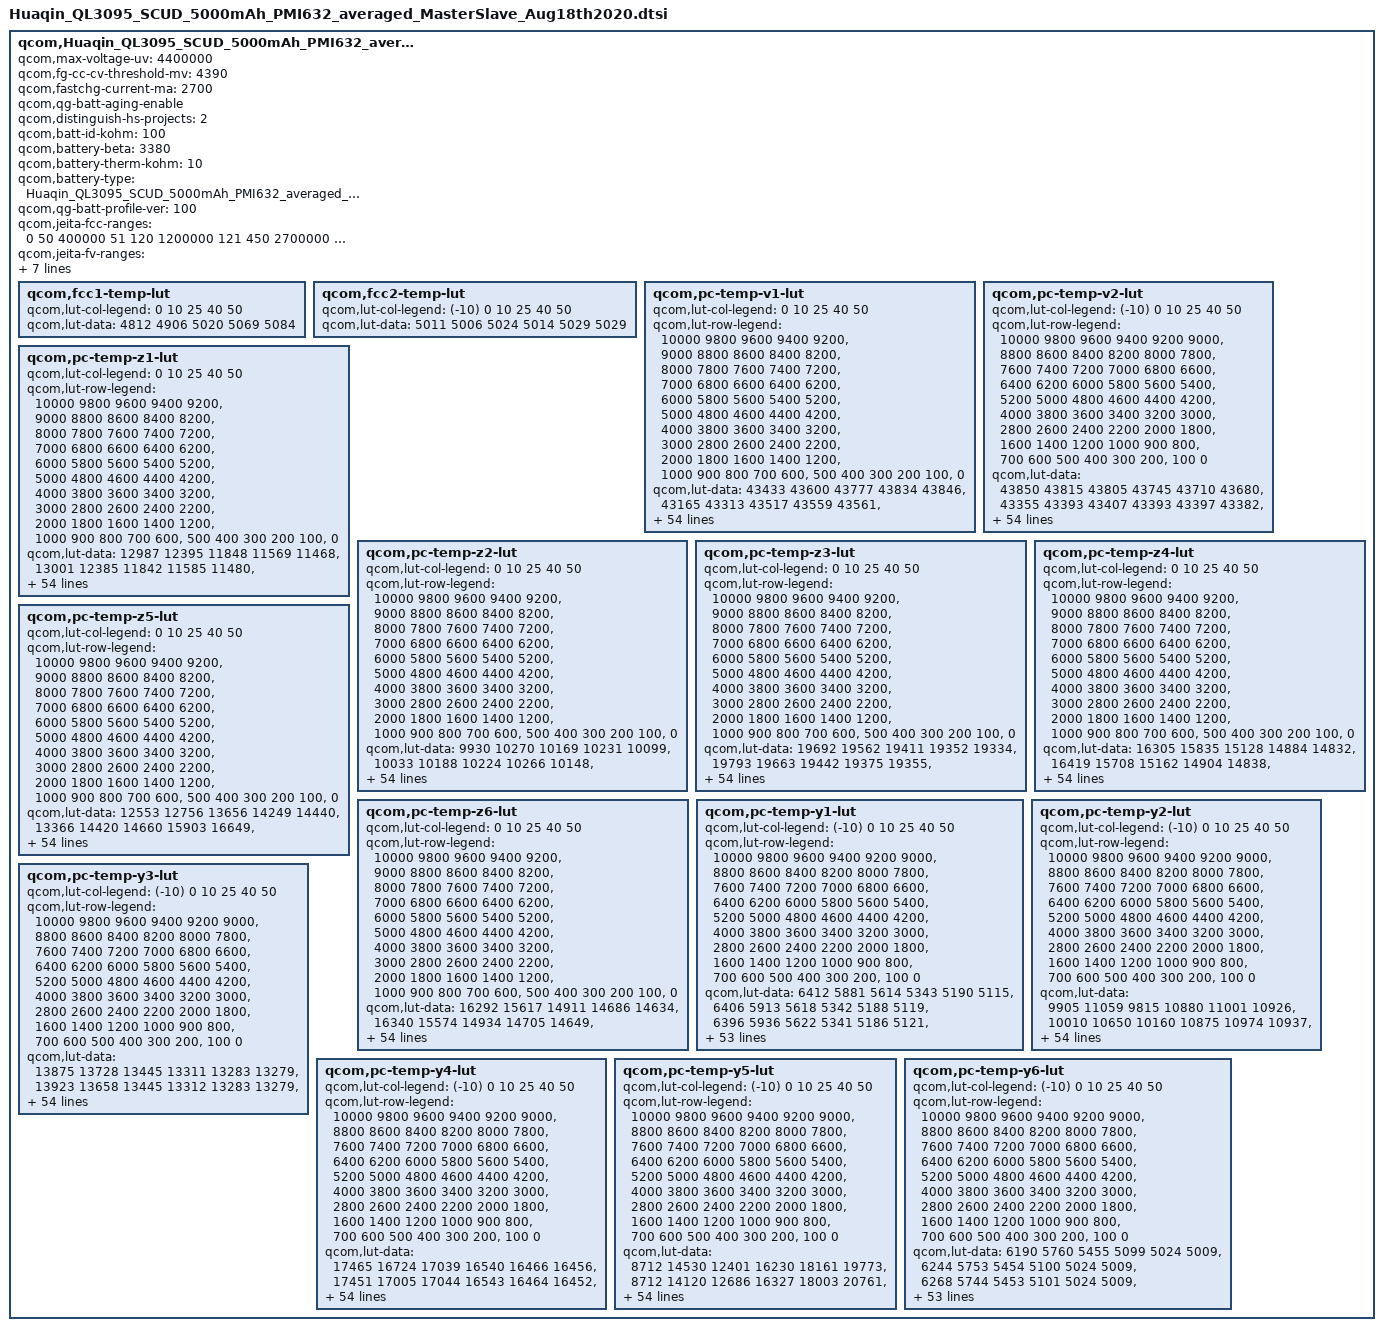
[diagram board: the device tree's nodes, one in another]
qcom,Huaqin_QL3095_SCUD_5000mAh_PMI632_averaged_MasterSlave_Aug18th2020 {
    /* Huaqin_QL3095_SCUD_5000mAh_PMI632_averaged_MasterSlave_Aug18th2020 */
	qcom,max-voltage-uv = <4400000>;
	qcom,fg-cc-cv-threshold-mv = <4390>;
	qcom,fastchg-current-ma = <2700>;
	/* HS60 add for SR-ZQL1695-01-357 Import battery aging by gaochao at 2019/08/29 start */
	qcom,qg-batt-aging-enable;
	/* HS60 add for SR-ZQL1695-01-357 Import battery aging by gaochao at 2019/08/29 end */
	/* HS50 add for SR-QL3095-01-67 Distinguish HS60, HS70 and HS50 charging by wenyaqi at 2020/8/3 start */
	qcom,distinguish-hs-projects = <2>;
	/* HS50 add for SR-QL3095-01-67 Distinguish HS60, HS70 and HS50 charging by wenyaqi at 2020/8/3 end */
	qcom,batt-id-kohm = <100>;
	/* HS50 add for HS50-186 fix hw jeita by wenyaqi at 2020/8/22 start */
	qcom,battery-beta = <3380>;
	/* HS50 add for HS50-186 fix hw jeita by wenyaqi at 2020/8/22 end */
	qcom,battery-therm-kohm = <10>;

	/* HS50 add for SR-QL3095-01-91 Import SCDU 5000mAh battery profile by zhangjin at 2020/8/19 start */
	qcom,battery-type = "Huaqin_QL3095_SCUD_5000mAh_PMI632_averaged_MasterSlave_Aug18th2020";
	/* HS50 add for SR-QL3095-01-91 Import SCDU 5000mAh battery profile by zhangjin at 2020/8/19 end */
	qcom,qg-batt-profile-ver = <100>;

	qcom,jeita-fcc-ranges = <0   50   400000
				 51   120   1200000
				 121 450  2700000
				 451 500  2200000>;
	qcom,jeita-fv-ranges =  <0   50  4400000
				 51   120  4400000
				 121 450  4400000
				 451 500  4200000>;

	/* HS60 add for SR-ZQL1695-01-357 Import battery aging by gaochao at 2019/08/29 start */
	qcom,vfloat-ranges = <0 299 4400000
	                      300 399 4380000
                              400 699 4360000
                              700 999 4340000
                              1000 9999 4290000>;

	qcom,vbat-rechg-ranges = <0 299 4330000
                                  300 399 4310000
                                  400 699 4290000
                                  700 999 4270000
                                  1000 9999 4220000>;
	/* HS60 add for SR-ZQL1695-01-357 Import battery aging by gaochao at 2019/08/29 end */

	/* COOL = 15 DegC, WARM = 45 DegC */
	/* HS50 add for HS50-186 fix hw jeita by wenyaqi at 2020/8/22 start */
	qcom,jeita-soft-thresholds = <0x2554 0xFDC>;
	/* COLD = 0 DegC, HOT = 50 DegC */
	qcom,jeita-hard-thresholds = <0x36B9 0xDBF>;
	/* HS50 add for HS50-186 fix hw jeita by wenyaqi at 2020/8/22 end */

	qcom,fcc1-temp-lut {
		qcom,lut-col-legend = <0 10 25 40 50>;
		qcom,lut-data = <4812 4906 5020 5069 5084>;
	};

	qcom,fcc2-temp-lut {
		qcom,lut-col-legend = <(-10) 0 10 25 40 50>;
		qcom,lut-data = <5011 5006 5024 5014 5029 5029>;
	};

	qcom,pc-temp-v1-lut {
		qcom,lut-col-legend = <0 10 25 40 50>;
		qcom,lut-row-legend = <10000 9800 9600 9400 9200>,
			<9000 8800 8600 8400 8200>,
			<8000 7800 7600 7400 7200>,
			<7000 6800 6600 6400 6200>,
			<6000 5800 5600 5400 5200>,
			<5000 4800 4600 4400 4200>,
			<4000 3800 3600 3400 3200>,
			<3000 2800 2600 2400 2200>,
			<2000 1800 1600 1400 1200>,
			<1000 900 800 700 600>,
			<500 400 300 200 100>,
			<0>;
		qcom,lut-data = <43433 43600 43777 43834 43846>,
			<43165 43313 43517 43559 43561>,
			<42925 43054 43243 43296 43301>,
			<42697 42821 42985 43042 43053>,
			<42477 42599 42746 42802 42814>,
			<42265 42378 42516 42571 42585>,
			<42060 42162 42290 42342 42357>,
			<41858 41952 42071 42115 42131>,
			<41664 41747 41855 41891 41906>,
			<41486 41549 41639 41671 41683>,
			<41331 41376 41432 41456 41462>,
			<41155 41217 41253 41249 41245>,
			<40908 41026 41087 41054 41033>,
			<40612 40756 40881 40852 40826>,
			<40339 40465 40596 40614 40617>,
			<40076 40217 40318 40369 40413>,
			<39859 39987 40110 40176 40228>,
			<39726 39818 39935 40018 40064>,
			<39632 39719 39793 39871 39906>,
			<39536 39636 39688 39735 39754>,
			<39428 39521 39577 39596 39600>,
			<39317 39376 39401 39412 39415>,
			<39199 39211 39182 39176 39184>,
			<39072 38995 38986 38968 38977>,
			<38941 38768 38804 38810 38819>,
			<38797 38629 38655 38676 38686>,
			<38652 38539 38557 38568 38573>,
			<38545 38469 38480 38479 38476>,
			<38462 38408 38407 38394 38386>,
			<38398 38358 38337 38311 38301>,
			<38351 38313 38274 38234 38223>,
			<38314 38272 38217 38165 38152>,
			<38282 38237 38165 38103 38087>,
			<38252 38207 38118 38048 38026>,
			<38227 38182 38078 38000 37973>,
			<38205 38156 38040 37955 37922>,
			<38187 38133 38006 37909 37867>,
			<38163 38104 37972 37863 37810>,
			<38117 38054 37922 37803 37741>,
			<38046 37974 37846 37722 37654>,
			<37960 37881 37753 37627 37554>,
			<37841 37773 37648 37521 37447>,
			<37703 37645 37522 37397 37324>,
			<37539 37481 37364 37246 37170>,
			<37386 37322 37211 37099 37029>,
			<37283 37213 37111 37004 36937>,
			<37255 37186 37080 36976 36909>,
			<37245 37160 37060 36957 36894>,
			<37211 37137 37045 36945 36878>,
			<37176 37109 37013 36911 36838>,
			<37046 36962 36849 36718 36626>,
			<36633 36548 36435 36304 36206>,
			<36082 35988 35872 35740 35642>,
			<35330 35226 35105 34971 34871>,
			<34143 34039 33916 33780 33675>,
			<30000 30000 30000 30000 30000>;
	};

	qcom,pc-temp-v2-lut {
		qcom,lut-col-legend = <(-10) 0 10 25 40 50>;
		qcom,lut-row-legend = <10000 9800 9600 9400 9200 9000>,
			<8800 8600 8400 8200 8000 7800>,
			<7600 7400 7200 7000 6800 6600>,
			<6400 6200 6000 5800 5600 5400>,
			<5200 5000 4800 4600 4400 4200>,
			<4000 3800 3600 3400 3200 3000>,
			<2800 2600 2400 2200 2000 1800>,
			<1600 1400 1200 1000 900 800>,
			<700 600 500 400 300 200>,
			<100 0>;
		qcom,lut-data = <43850 43815 43805 43745 43710 43680>,
			<43355 43393 43407 43393 43397 43382>,
			<42952 43021 43054 43077 43107 43104>,
			<42672 42706 42754 42803 42844 42846>,
			<42481 42433 42498 42565 42606 42608>,
			<42271 42201 42259 42337 42376 42376>,
			<41896 42018 42034 42109 42147 42146>,
			<41536 41851 41816 41886 41922 41919>,
			<41487 41636 41573 41665 41700 41697>,
			<41539 41351 41295 41445 41481 41478>,
			<41571 41176 41095 41237 41265 41263>,
			<41445 41143 41009 41054 41051 41050>,
			<41164 41120 40935 40875 40840 40841>,
			<40765 40953 40722 40658 40636 40639>,
			<40091 40308 40236 40394 40437 40441>,
			<39630 39809 39880 40148 40243 40251>,
			<39500 39669 39749 39941 40050 40069>,
			<39408 39571 39649 39759 39866 39895>,
			<39231 39426 39518 39622 39710 39734>,
			<38928 39234 39366 39522 39577 39585>,
			<38678 39049 39197 39400 39424 39420>,
			<38508 38898 38994 39192 39213 39209>,
			<38369 38751 38787 38952 38988 38991>,
			<38294 38563 38628 38764 38802 38806>,
			<38245 38320 38498 38605 38635 38639>,
			<38199 38161 38362 38471 38496 38499>,
			<38152 38108 38183 38361 38386 38388>,
			<38105 38072 38027 38265 38290 38291>,
			<38057 38033 37968 38177 38202 38201>,
			<38009 37995 37938 38095 38122 38117>,
			<37960 37958 37909 38020 38049 38043>,
			<37912 37919 37879 37947 37982 37976>,
			<37864 37880 37847 37882 37920 37914>,
			<37813 37841 37815 37830 37857 37851>,
			<37761 37804 37782 37788 37797 37790>,
			<37708 37763 37743 37744 37728 37714>,
			<37653 37718 37697 37695 37641 37607>,
			<37595 37668 37643 37640 37550 37494>,
			<37532 37610 37577 37573 37469 37405>,
			<37465 37543 37499 37493 37393 37327>,
			<37396 37468 37413 37406 37312 37245>,
			<37325 37377 37314 37310 37227 37158>,
			<37252 37273 37216 37200 37122 37054>,
			<37181 37160 37126 37063 36980 36917>,
			<37108 37053 37024 36944 36855 36795>,
			<37019 36958 36921 36871 36807 36753>,
			<36971 36917 36865 36853 36797 36744>,
			<36922 36881 36818 36834 36784 36729>,
			<36855 36828 36769 36808 36760 36706>,
			<36759 36747 36690 36755 36697 36633>,
			<36578 36580 36538 36593 36456 36361>,
			<36248 36197 36216 36158 35979 35871>,
			<35706 35598 35663 35545 35344 35228>,
			<34886 34726 34869 34705 34468 34334>,
			<33559 33344 33625 33352 33190 33052>,
			<29210 29419 28513 28298 28499 28549>;
	};

	qcom,pc-temp-z1-lut {
		qcom,lut-col-legend = <0 10 25 40 50>;
		qcom,lut-row-legend = <10000 9800 9600 9400 9200>,
			<9000 8800 8600 8400 8200>,
			<8000 7800 7600 7400 7200>,
			<7000 6800 6600 6400 6200>,
			<6000 5800 5600 5400 5200>,
			<5000 4800 4600 4400 4200>,
			<4000 3800 3600 3400 3200>,
			<3000 2800 2600 2400 2200>,
			<2000 1800 1600 1400 1200>,
			<1000 900 800 700 600>,
			<500 400 300 200 100>,
			<0>;
		qcom,lut-data = <12987 12395 11848 11569 11468>,
			<13001 12385 11842 11585 11480>,
			<12990 12381 11847 11582 11480>,
			<12978 12380 11847 11577 11479>,
			<12985 12381 11838 11573 11477>,
			<13001 12374 11827 11568 11474>,
			<13007 12357 11820 11564 11472>,
			<12985 12347 11814 11559 11471>,
			<12951 12343 11811 11557 11470>,
			<12937 12341 11810 11557 11470>,
			<12937 12334 11810 11558 11470>,
			<12935 12319 11809 11558 11470>,
			<12913 12300 11807 11558 11473>,
			<12868 12266 11802 11558 11475>,
			<12833 12235 11783 11549 11471>,
			<12798 12232 11768 11535 11463>,
			<12772 12236 11767 11533 11461>,
			<12763 12238 11768 11535 11462>,
			<12757 12240 11769 11538 11463>,
			<12754 12243 11776 11541 11465>,
			<12760 12247 11783 11544 11466>,
			<12768 12255 11785 11544 11466>,
			<12772 12260 11786 11543 11465>,
			<12776 12261 11787 11543 11465>,
			<12780 12262 11790 11544 11465>,
			<12783 12265 11792 11545 11466>,
			<12786 12276 11794 11547 11467>,
			<12791 12284 11796 11549 11469>,
			<12798 12284 11800 11552 11471>,
			<12804 12281 11805 11555 11473>,
			<12807 12281 11811 11558 11476>,
			<12808 12286 11814 11561 11479>,
			<12810 12290 11817 11564 11482>,
			<12823 12292 11820 11568 11486>,
			<12840 12294 11823 11572 11489>,
			<12844 12298 11827 11576 11492>,
			<12842 12314 11831 11580 11495>,
			<12842 12332 11837 11584 11498>,
			<12856 12339 11840 11587 11501>,
			<12878 12343 11844 11590 11503>,
			<12889 12344 11847 11592 11504>,
			<12894 12350 11850 11595 11507>,
			<12895 12354 11853 11598 11509>,
			<12899 12355 11859 11602 11511>,
			<12908 12370 11868 11606 11514>,
			<12938 12370 11876 11609 11515>,
			<12919 12384 11879 11609 11514>,
			<12909 12364 11877 11609 11516>,
			<12922 12368 11884 11610 11517>,
			<12911 12375 11875 11614 11520>,
			<12952 12379 11892 11620 11525>,
			<12957 12395 11893 11629 11532>,
			<12962 12420 11904 11640 11542>,
			<12974 12437 11923 11653 11555>,
			<12974 12437 11923 11653 11555>,
			<12974 12437 11923 11653 11555>;
	};

	qcom,pc-temp-z2-lut {
		qcom,lut-col-legend = <0 10 25 40 50>;
		qcom,lut-row-legend = <10000 9800 9600 9400 9200>,
			<9000 8800 8600 8400 8200>,
			<8000 7800 7600 7400 7200>,
			<7000 6800 6600 6400 6200>,
			<6000 5800 5600 5400 5200>,
			<5000 4800 4600 4400 4200>,
			<4000 3800 3600 3400 3200>,
			<3000 2800 2600 2400 2200>,
			<2000 1800 1600 1400 1200>,
			<1000 900 800 700 600>,
			<500 400 300 200 100>,
			<0>;
		qcom,lut-data = <9930 10270 10169 10231 10099>,
			<10033 10188 10224 10266 10148>,
			<10075 10163 10287 10378 10263>,
			<10100 10166 10315 10460 10401>,
			<10113 10168 10313 10449 10391>,
			<10123 10169 10311 10413 10306>,
			<10127 10170 10419 10390 10256>,
			<10128 10170 10651 10379 10210>,
			<10129 10169 10706 10369 10168>,
			<10129 10168 10489 10349 10162>,
			<10129 10172 10297 10325 10156>,
			<10128 10182 10400 10320 10156>,
			<10111 10193 10643 10324 10166>,
			<10079 10204 10710 10331 10182>,
			<10066 10213 10548 10383 10205>,
			<10066 10219 10395 10460 10234>,
			<10067 10223 10363 10447 10245>,
			<10075 10230 10335 10299 10245>,
			<10095 10254 10330 10207 10247>,
			<10115 10291 10357 10226 10267>,
			<10132 10326 10399 10271 10302>,
			<10150 10365 10465 10365 10339>,
			<10168 10398 10547 10562 10385>,
			<10186 10429 10563 10657 10410>,
			<10206 10453 10514 10516 10408>,
			<10229 10458 10473 10342 10402>,
			<10253 10455 10483 10325 10406>,
			<10271 10452 10507 10337 10424>,
			<10287 10449 10517 10355 10430>,
			<10299 10448 10522 10432 10386>,
			<10307 10448 10526 10507 10326>,
			<10313 10458 10528 10510 10295>,
			<10321 10470 10531 10498 10274>,
			<10335 10479 10536 10483 10268>,
			<10351 10486 10547 10459 10278>,
			<10364 10495 10560 10438 10296>,
			<10374 10506 10568 10433 10325>,
			<10386 10518 10576 10439 10369>,
			<10405 10535 10588 10459 10409>,
			<10428 10556 10610 10545 10449>,
			<10446 10564 10625 10616 10474>,
			<10460 10557 10628 10609 10466>,
			<10478 10552 10628 10582 10449>,
			<10515 10573 10627 10522 10441>,
			<10802 10739 10673 10512 10447>,
			<10859 10804 10687 10520 10450>,
			<10762 10809 10672 10504 10448>,
			<10475 10801 10664 10497 10448>,
			<10678 10791 10654 10514 10456>,
			<10645 10815 10656 10591 10543>,
			<10406 10852 10697 10535 10486>,
			<10703 10813 10644 10425 10262>,
			<10202 10729 10573 10368 10224>,
			<9771 10646 10483 10314 10170>,
			<9771 10646 10483 10314 10170>,
			<9771 10646 10483 10314 10170>;
	};

	qcom,pc-temp-z3-lut {
		qcom,lut-col-legend = <0 10 25 40 50>;
		qcom,lut-row-legend = <10000 9800 9600 9400 9200>,
			<9000 8800 8600 8400 8200>,
			<8000 7800 7600 7400 7200>,
			<7000 6800 6600 6400 6200>,
			<6000 5800 5600 5400 5200>,
			<5000 4800 4600 4400 4200>,
			<4000 3800 3600 3400 3200>,
			<3000 2800 2600 2400 2200>,
			<2000 1800 1600 1400 1200>,
			<1000 900 800 700 600>,
			<500 400 300 200 100>,
			<0>;
		qcom,lut-data = <19692 19562 19411 19352 19334>,
			<19793 19663 19442 19375 19355>,
			<19819 19688 19474 19398 19373>,
			<19830 19680 19485 19412 19384>,
			<19827 19669 19485 19412 19385>,
			<19815 19662 19485 19411 19385>,
			<19800 19655 19490 19411 19384>,
			<19783 19647 19499 19410 19383>,
			<19764 19638 19500 19410 19382>,
			<19749 19629 19485 19407 19380>,
			<19735 19618 19470 19403 19377>,
			<19727 19606 19469 19401 19376>,
			<19732 19596 19472 19400 19376>,
			<19742 19590 19472 19399 19375>,
			<19746 19584 19467 19398 19374>,
			<19735 19577 19461 19398 19372>,
			<19717 19567 19454 19394 19368>,
			<19693 19554 19444 19376 19357>,
			<19661 19530 19433 19363 19349>,
			<19642 19506 19422 19358 19346>,
			<19635 19505 19415 19355 19343>,
			<19631 19520 19422 19359 19344>,
			<19633 19535 19438 19373 19352>,
			<19645 19547 19442 19381 19356>,
			<19659 19556 19435 19370 19347>,
			<19670 19557 19427 19356 19333>,
			<19679 19554 19424 19353 19333>,
			<19681 19549 19421 19352 19341>,
			<19676 19545 19421 19352 19350>,
			<19669 19540 19424 19364 19359>,
			<19662 19536 19427 19378 19367>,
			<19652 19534 19431 19382 19367>,
			<19644 19531 19434 19385 19366>,
			<19637 19528 19435 19386 19364>,
			<19631 19525 19435 19382 19360>,
			<19624 19522 19435 19375 19354>,
			<19616 19520 19433 19370 19349>,
			<19609 19519 19428 19366 19345>,
			<19605 19517 19426 19364 19344>,
			<19602 19514 19424 19364 19344>,
			<19597 19512 19422 19365 19344>,
			<19591 19507 19420 19364 19345>,
			<19582 19501 19416 19363 19346>,
			<19570 19494 19413 19358 19348>,
			<19507 19464 19405 19354 19346>,
			<19481 19452 19390 19346 19338>,
			<19455 19443 19390 19346 19336>,
			<19365 19442 19391 19346 19329>,
			<19409 19441 19383 19338 19325>,
			<19403 19431 19380 19331 19321>,
			<19371 19426 19373 19342 19333>,
			<19395 19426 19380 19348 19347>,
			<19350 19426 19384 19353 19346>,
			<19313 19424 19380 19347 19346>,
			<19313 19424 19380 19347 19346>,
			<19313 19424 19380 19347 19346>;
	};

	qcom,pc-temp-z4-lut {
		qcom,lut-col-legend = <0 10 25 40 50>;
		qcom,lut-row-legend = <10000 9800 9600 9400 9200>,
			<9000 8800 8600 8400 8200>,
			<8000 7800 7600 7400 7200>,
			<7000 6800 6600 6400 6200>,
			<6000 5800 5600 5400 5200>,
			<5000 4800 4600 4400 4200>,
			<4000 3800 3600 3400 3200>,
			<3000 2800 2600 2400 2200>,
			<2000 1800 1600 1400 1200>,
			<1000 900 800 700 600>,
			<500 400 300 200 100>,
			<0>;
		qcom,lut-data = <16305 15835 15128 14884 14832>,
			<16419 15708 15162 14904 14838>,
			<16155 15561 15071 14877 14825>,
			<15827 15377 14994 14841 14805>,
			<15630 15214 14936 14814 14787>,
			<15476 15109 14884 14790 14770>,
			<15355 15027 14830 14769 14754>,
			<15259 14965 14778 14751 14740>,
			<15181 14915 14756 14735 14727>,
			<15119 14875 14752 14721 14716>,
			<15068 14845 14750 14709 14705>,
			<15021 14822 14733 14702 14698>,
			<14967 14799 14703 14698 14693>,
			<14917 14771 14694 14696 14689>,
			<14890 14750 14705 14695 14685>,
			<14878 14747 14714 14694 14682>,
			<14867 14746 14709 14692 14677>,
			<14852 14745 14699 14682 14669>,
			<14836 14741 14690 14673 14661>,
			<14821 14736 14681 14664 14654>,
			<14805 14728 14675 14658 14648>,
			<14790 14715 14684 14664 14654>,
			<14776 14708 14708 14697 14692>,
			<14761 14742 14735 14730 14730>,
			<14754 14797 14775 14760 14756>,
			<14761 14809 14802 14782 14774>,
			<14776 14806 14798 14782 14773>,
			<14783 14801 14787 14771 14753>,
			<14787 14794 14775 14757 14731>,
			<14789 14783 14760 14735 14711>,
			<14787 14773 14747 14710 14692>,
			<14782 14765 14735 14694 14680>,
			<14777 14757 14724 14681 14670>,
			<14770 14749 14717 14677 14666>,
			<14763 14743 14713 14676 14664>,
			<14756 14737 14710 14675 14664>,
			<14750 14732 14711 14677 14665>,
			<14744 14729 14711 14681 14669>,
			<14739 14730 14713 14686 14675>,
			<14734 14734 14719 14693 14684>,
			<14733 14736 14723 14697 14691>,
			<14734 14733 14719 14695 14687>,
			<14734 14728 14712 14691 14681>,
			<14728 14722 14708 14693 14682>,
			<14710 14701 14691 14685 14677>,
			<14709 14691 14679 14674 14664>,
			<14734 14688 14673 14668 14662>,
			<14823 14682 14663 14655 14655>,
			<14769 14677 14658 14647 14642>,
			<14774 14682 14656 14644 14635>,
			<14807 14690 14673 14653 14648>,
			<14801 14704 14679 14661 14647>,
			<14868 14709 14678 14657 14649>,
			<14916 14712 14684 14665 14650>,
			<14916 14712 14684 14665 14650>,
			<14916 14712 14684 14665 14650>;
	};

	qcom,pc-temp-z5-lut {
		qcom,lut-col-legend = <0 10 25 40 50>;
		qcom,lut-row-legend = <10000 9800 9600 9400 9200>,
			<9000 8800 8600 8400 8200>,
			<8000 7800 7600 7400 7200>,
			<7000 6800 6600 6400 6200>,
			<6000 5800 5600 5400 5200>,
			<5000 4800 4600 4400 4200>,
			<4000 3800 3600 3400 3200>,
			<3000 2800 2600 2400 2200>,
			<2000 1800 1600 1400 1200>,
			<1000 900 800 700 600>,
			<500 400 300 200 100>,
			<0>;
		qcom,lut-data = <12553 12756 13656 14249 14440>,
			<13366 14420 14660 15903 16649>,
			<14000 15468 16084 18080 18869>,
			<14545 16082 17096 19625 20487>,
			<15020 16639 17659 20004 20842>,
			<15433 17354 18243 20199 20919>,
			<15804 18134 19706 20511 21017>,
			<16131 18928 21904 21102 21301>,
			<16441 19864 22717 21771 21726>,
			<16756 20767 22158 22367 22286>,
			<17046 21383 21644 22985 23057>,
			<17455 21909 23279 23632 23862>,
			<18775 22740 26725 24286 24666>,
			<20776 25422 28138 25286 25678>,
			<21461 28085 30696 29015 27726>,
			<21326 28065 32909 33902 30315>,
			<21035 26675 31259 33477 30513>,
			<20447 25059 27656 26412 26994>,
			<19423 22960 26566 22032 24326>,
			<18959 21104 26865 22705 25587>,
			<19447 22587 27489 24377 28563>,
			<20569 31497 33794 28843 31765>,
			<22523 40779 46001 39946 35948>,
			<27078 48325 48599 45353 38053>,
			<32579 54494 39803 35630 30688>,
			<40013 54724 30776 22772 19994>,
			<47811 48601 27083 19451 18210>,
			<49664 42392 24560 18042 18232>,
			<47876 39086 24080 17687 18482>,
			<45489 36588 24450 19277 19939>,
			<43100 35773 25086 21994 22252>,
			<39745 35580 26534 25129 24546>,
			<37825 35580 29057 29001 27109>,
			<37162 35825 31683 31121 28684>,
			<36688 36336 34942 32115 29596>,
			<36019 37030 36993 32623 30116>,
			<34947 38355 37053 32114 29844>,
			<34446 39608 36613 30714 28908>,
			<35512 40123 35881 29826 28011>,
			<37176 40452 34482 29226 27116>,
			<37456 40231 32947 28664 26143>,
			<35964 37435 31517 27491 24916>,
			<35239 34722 30286 25575 23928>,
			<34952 33213 29142 23441 24250>,
			<33309 34309 29927 23662 24234>,
			<28766 34160 27673 21961 22202>,
			<26189 30627 28418 22286 21380>,
			<17006 30912 29987 24431 20399>,
			<18749 31211 27398 23347 22110>,
			<18596 26848 27162 22688 23751>,
			<17641 25017 21773 22804 23076>,
			<16640 21998 20587 19753 22917>,
			<13208 20657 20448 20197 21173>,
			<12242 19222 18867 17868 19687>,
			<12242 19222 18867 17868 19687>,
			<12242 19222 18867 17868 19687>;
	};

	qcom,pc-temp-z6-lut {
		qcom,lut-col-legend = <0 10 25 40 50>;
		qcom,lut-row-legend = <10000 9800 9600 9400 9200>,
			<9000 8800 8600 8400 8200>,
			<8000 7800 7600 7400 7200>,
			<7000 6800 6600 6400 6200>,
			<6000 5800 5600 5400 5200>,
			<5000 4800 4600 4400 4200>,
			<4000 3800 3600 3400 3200>,
			<3000 2800 2600 2400 2200>,
			<2000 1800 1600 1400 1200>,
			<1000 900 800 700 600>,
			<500 400 300 200 100>,
			<0>;
		qcom,lut-data = <16292 15617 14911 14686 14634>,
			<16340 15574 14934 14705 14649>,
			<16191 15508 14905 14702 14649>,
			<16004 15400 14876 14697 14649>,
			<15878 15295 14847 14689 14646>,
			<15773 15227 14819 14676 14637>,
			<15684 15172 14797 14665 14629>,
			<15608 15127 14778 14657 14623>,
			<15543 15089 14763 14649 14617>,
			<15489 15056 14751 14641 14611>,
			<15444 15028 14741 14634 14604>,
			<15401 15004 14730 14630 14600>,
			<15354 14979 14720 14627 14598>,
			<15308 14947 14714 14625 14596>,
			<15271 14920 14711 14623 14593>,
			<15242 14906 14708 14620 14589>,
			<15216 14898 14701 14614 14583>,
			<15189 14890 14691 14602 14574>,
			<15163 14877 14682 14591 14567>,
			<15146 14865 14674 14585 14561>,
			<15134 14864 14668 14580 14558>,
			<15127 14868 14676 14585 14561>,
			<15126 14874 14694 14608 14582>,
			<15130 14895 14709 14624 14599>,
			<15134 14925 14723 14630 14603>,
			<15144 14931 14731 14634 14606>,
			<15157 14929 14729 14633 14606>,
			<15163 14926 14723 14628 14602>,
			<15164 14922 14718 14623 14598>,
			<15163 14916 14715 14620 14595>,
			<15160 14911 14712 14617 14591>,
			<15156 14907 14709 14614 14587>,
			<15151 14904 14707 14611 14583>,
			<15147 14900 14706 14609 14580>,
			<15143 14897 14705 14606 14576>,
			<15139 14895 14705 14603 14573>,
			<15136 14895 14705 14603 14573>,
			<15134 14895 14704 14602 14572>,
			<15135 14897 14704 14603 14572>,
			<15137 14901 14707 14606 14576>,
			<15140 14902 14709 14609 14580>,
			<15144 14902 14707 14608 14579>,
			<15147 14901 14704 14606 14577>,
			<15149 14901 14703 14605 14579>,
			<15130 14889 14696 14600 14576>,
			<15121 14883 14685 14592 14567>,
			<15118 14878 14683 14589 14564>,
			<15112 14875 14679 14584 14558>,
			<15112 14873 14674 14576 14550>,
			<15113 14874 14673 14572 14545>,
			<15120 14880 14679 14583 14558>,
			<15138 14892 14689 14592 14568>,
			<15154 14904 14695 14595 14571>,
			<15176 14916 14701 14599 14574>,
			<15176 14916 14701 14599 14574>,
			<15176 14916 14701 14599 14574>;
	};

	qcom,pc-temp-y1-lut {
		qcom,lut-col-legend = <(-10) 0 10 25 40 50>;
		qcom,lut-row-legend = <10000 9800 9600 9400 9200 9000>,
			<8800 8600 8400 8200 8000 7800>,
			<7600 7400 7200 7000 6800 6600>,
			<6400 6200 6000 5800 5600 5400>,
			<5200 5000 4800 4600 4400 4200>,
			<4000 3800 3600 3400 3200 3000>,
			<2800 2600 2400 2200 2000 1800>,
			<1600 1400 1200 1000 900 800>,
			<700 600 500 400 300 200>,
			<100 0>;
		qcom,lut-data = <6412 5881 5614 5343 5190 5115>,
			<6406 5913 5618 5342 5188 5119>,
			<6396 5936 5622 5341 5186 5121>,
			<6387 5951 5626 5340 5185 5122>,
			<6379 5960 5629 5339 5183 5122>,
			<6376 5965 5630 5338 5182 5123>,
			<6377 5962 5629 5338 5181 5121>,
			<6378 5954 5628 5337 5180 5119>,
			<6383 5951 5625 5336 5178 5117>,
			<6393 5941 5617 5335 5177 5116>,
			<6399 5935 5612 5334 5175 5115>,
			<6388 5935 5615 5333 5173 5114>,
			<6373 5938 5620 5332 5172 5114>,
			<6373 5938 5622 5332 5170 5112>,
			<6386 5939 5624 5332 5167 5109>,
			<6395 5941 5626 5333 5166 5108>,
			<6406 5954 5631 5339 5169 5110>,
			<6418 5970 5637 5346 5173 5112>,
			<6414 5971 5639 5347 5173 5112>,
			<6395 5968 5640 5346 5170 5111>,
			<6384 5966 5641 5344 5168 5110>,
			<6382 5972 5641 5342 5168 5110>,
			<6380 5980 5642 5340 5168 5110>,
			<6381 5978 5642 5340 5168 5110>,
			<6389 5962 5643 5343 5169 5111>,
			<6394 5952 5643 5346 5170 5112>,
			<6386 5957 5647 5348 5171 5112>,
			<6374 5966 5653 5349 5173 5113>,
			<6374 5967 5656 5351 5175 5115>,
			<6388 5962 5661 5354 5177 5117>,
			<6397 5958 5663 5357 5179 5119>,
			<6390 5955 5659 5359 5182 5121>,
			<6378 5953 5654 5361 5185 5123>,
			<6369 5955 5650 5364 5188 5126>,
			<6355 5967 5642 5369 5191 5128>,
			<6348 5973 5638 5372 5194 5130>,
			<6349 5963 5637 5373 5197 5132>,
			<6351 5948 5636 5375 5200 5133>,
			<6354 5944 5640 5379 5202 5135>,
			<6357 5947 5651 5388 5204 5136>,
			<6362 5948 5655 5393 5206 5138>,
			<6373 5944 5644 5390 5209 5140>,
			<6380 5938 5639 5388 5212 5142>,
			<6358 5926 5652 5392 5215 5145>,
			<6346 5938 5641 5397 5220 5150>,
			<6367 5967 5665 5414 5225 5153>,
			<6363 5967 5652 5405 5227 5154>,
			<6402 5962 5649 5414 5225 5153>,
			<6432 5953 5653 5411 5225 5152>,
			<6405 5955 5657 5406 5224 5151>,
			<6392 5968 5660 5404 5225 5153>,
			<6384 5970 5712 5410 5233 5160>,
			<6397 6007 5736 5430 5245 5167>,
			<6416 6006 5684 5439 5255 5177>,
			<6416 6006 5684 5439 5255 5177>,
			<6416 6006 5684 5439 5255 5177>;
	};

	qcom,pc-temp-y2-lut {
		qcom,lut-col-legend = <(-10) 0 10 25 40 50>;
		qcom,lut-row-legend = <10000 9800 9600 9400 9200 9000>,
			<8800 8600 8400 8200 8000 7800>,
			<7600 7400 7200 7000 6800 6600>,
			<6400 6200 6000 5800 5600 5400>,
			<5200 5000 4800 4600 4400 4200>,
			<4000 3800 3600 3400 3200 3000>,
			<2800 2600 2400 2200 2000 1800>,
			<1600 1400 1200 1000 900 800>,
			<700 600 500 400 300 200>,
			<100 0>;
		qcom,lut-data = <9905 11059 9815 10880 11001 10926>,
			<10010 10650 10160 10875 10974 10937>,
			<10140 10371 10372 10862 10940 10941>,
			<10266 10198 10484 10846 10906 10939>,
			<10364 10111 10527 10830 10877 10932>,
			<10406 10088 10534 10821 10862 10922>,
			<10395 10194 10420 10814 10856 10906>,
			<10376 10357 10253 10806 10853 10885>,
			<10387 10377 10294 10805 10845 10872>,
			<10457 10322 10616 10804 10826 10859>,
			<10556 10287 10804 10800 10812 10851>,
			<10753 10320 10639 10765 10804 10850>,
			<10964 10399 10410 10718 10795 10851>,
			<10846 10501 10414 10735 10807 10853>,
			<10124 10669 10599 10857 10865 10856>,
			<9684 10900 10775 10943 10918 10862>,
			<9680 11390 10881 10959 10954 10870>,
			<9678 11920 10980 10970 10995 10882>,
			<9676 11888 11097 11010 11068 10922>,
			<9675 11243 11230 11116 11194 11025>,
			<9674 10652 11369 11181 11251 11089>,
			<9672 10347 11559 11190 11222 11108>,
			<9670 10115 11718 11196 11184 11120>,
			<9669 9951 11584 11207 11167 11119>,
			<9668 9803 11023 11230 11142 11110>,
			<9667 9728 10744 11262 11134 11109>,
			<9666 9712 10885 11312 11157 11132>,
			<9666 9702 11055 11377 11196 11166>,
			<9665 9695 11066 11454 11247 11198>,
			<9665 9689 11023 11549 11321 11245>,
			<9664 9684 10942 11596 11388 11278>,
			<9664 9679 10539 11596 11454 11308>,
			<9664 9676 10063 11588 11515 11346>,
			<9664 9674 9893 11565 11558 11393>,
			<9663 9672 9785 11507 11595 11455>,
			<9663 9670 9731 11442 11603 11478>,
			<9663 9669 9710 11372 11521 11463>,
			<9663 9667 9697 11296 11431 11440>,
			<9663 9666 9689 11222 11420 11416>,
			<9663 9665 9683 11146 11420 11375>,
			<9663 9665 9679 11080 11419 11341>,
			<9663 9664 9677 11029 11398 11300>,
			<9662 9664 9674 10971 11373 11286>,
			<9662 9663 9671 10884 11348 11308>,
			<9662 9663 9669 10799 11247 11227>,
			<9662 9663 9671 10792 11122 11047>,
			<9662 9662 9670 10781 11141 11013>,
			<9662 9662 9670 10758 11178 11003>,
			<9661 9662 9671 10748 11199 11106>,
			<9661 9662 9671 10773 11210 11116>,
			<9660 9661 9670 10773 11165 11002>,
			<9660 9661 9669 10679 11067 10923>,
			<9659 9660 9666 10577 10989 10849>,
			<9658 9659 9662 10490 10924 10753>,
			<9658 9659 9662 10490 10924 10753>,
			<9658 9659 9662 10490 10924 10753>;
	};

	qcom,pc-temp-y3-lut {
		qcom,lut-col-legend = <(-10) 0 10 25 40 50>;
		qcom,lut-row-legend = <10000 9800 9600 9400 9200 9000>,
			<8800 8600 8400 8200 8000 7800>,
			<7600 7400 7200 7000 6800 6600>,
			<6400 6200 6000 5800 5600 5400>,
			<5200 5000 4800 4600 4400 4200>,
			<4000 3800 3600 3400 3200 3000>,
			<2800 2600 2400 2200 2000 1800>,
			<1600 1400 1200 1000 900 800>,
			<700 600 500 400 300 200>,
			<100 0>;
		qcom,lut-data = <13875 13728 13445 13311 13283 13279>,
			<13923 13658 13445 13312 13283 13279>,
			<13944 13616 13448 13313 13283 13279>,
			<13944 13594 13451 13314 13284 13279>,
			<13927 13586 13455 13315 13284 13280>,
			<13895 13585 13457 13316 13285 13280>,
			<13710 13625 13460 13317 13285 13280>,
			<13462 13686 13466 13319 13286 13280>,
			<13423 13662 13481 13319 13287 13281>,
			<13453 13481 13517 13320 13287 13282>,
			<13481 13368 13537 13321 13288 13283>,
			<13497 13403 13474 13325 13288 13284>,
			<13509 13457 13387 13330 13288 13284>,
			<13500 13465 13378 13330 13289 13284>,
			<13449 13453 13396 13326 13292 13284>,
			<13418 13441 13407 13321 13294 13284>,
			<13436 13432 13403 13318 13294 13284>,
			<13466 13423 13396 13315 13294 13284>,
			<13481 13402 13392 13315 13294 13285>,
			<13492 13355 13386 13317 13295 13288>,
			<13498 13329 13378 13318 13295 13289>,
			<13495 13332 13360 13315 13293 13286>,
			<13494 13338 13339 13310 13289 13282>,
			<13505 13337 13326 13306 13286 13280>,
			<13528 13327 13313 13302 13283 13279>,
			<13554 13319 13307 13300 13281 13278>,
			<13579 13319 13306 13299 13280 13278>,
			<13605 13321 13305 13299 13280 13278>,
			<13633 13330 13306 13297 13280 13277>,
			<13663 13352 13311 13295 13280 13277>,
			<13693 13376 13315 13293 13280 13276>,
			<13725 13395 13318 13292 13280 13276>,
			<13756 13414 13322 13292 13280 13277>,
			<13783 13438 13330 13292 13280 13277>,
			<13808 13466 13343 13293 13281 13278>,
			<13832 13494 13357 13294 13281 13278>,
			<13853 13520 13367 13295 13279 13277>,
			<13874 13546 13378 13297 13278 13275>,
			<13897 13572 13389 13298 13278 13275>,
			<13922 13598 13401 13300 13278 13276>,
			<13949 13624 13415 13302 13279 13277>,
			<13974 13653 13434 13305 13282 13278>,
			<14003 13683 13459 13307 13283 13278>,
			<14038 13714 13499 13306 13281 13278>,
			<14082 13757 13538 13308 13281 13276>,
			<14062 13749 13516 13309 13283 13279>,
			<14097 13780 13531 13313 13287 13283>,
			<14142 13817 13551 13319 13290 13285>,
			<14187 13841 13570 13326 13294 13288>,
			<14237 13869 13582 13331 13295 13288>,
			<14284 13893 13591 13332 13291 13284>,
			<14345 13911 13602 13327 13290 13283>,
			<14419 13995 13653 13335 13294 13287>,
			<14557 14111 13766 13348 13301 13293>,
			<14557 14111 13766 13348 13301 13293>,
			<14557 14111 13766 13348 13301 13293>;
	};

	qcom,pc-temp-y4-lut {
		qcom,lut-col-legend = <(-10) 0 10 25 40 50>;
		qcom,lut-row-legend = <10000 9800 9600 9400 9200 9000>,
			<8800 8600 8400 8200 8000 7800>,
			<7600 7400 7200 7000 6800 6600>,
			<6400 6200 6000 5800 5600 5400>,
			<5200 5000 4800 4600 4400 4200>,
			<4000 3800 3600 3400 3200 3000>,
			<2800 2600 2400 2200 2000 1800>,
			<1600 1400 1200 1000 900 800>,
			<700 600 500 400 300 200>,
			<100 0>;
		qcom,lut-data = <17465 16724 17039 16540 16466 16456>,
			<17451 17005 17044 16543 16464 16452>,
			<17444 17176 17046 16546 16463 16450>,
			<17441 17263 17048 16548 16462 16448>,
			<17443 17295 17047 16550 16462 16447>,
			<17449 17300 17047 16550 16462 16447>,
			<17663 17214 17040 16550 16462 16447>,
			<18014 17084 17024 16549 16463 16448>,
			<18169 17126 16982 16550 16464 16450>,
			<18255 17466 16867 16553 16467 16451>,
			<18288 17703 16805 16557 16471 16452>,
			<18192 17735 17044 16561 16475 16454>,
			<17991 17752 17378 16565 16479 16457>,
			<17759 17667 17353 16570 16483 16462>,
			<17437 17238 17027 16575 16488 16471>,
			<17244 16970 16845 16583 16493 16479>,
			<17210 16995 16897 16596 16502 16483>,
			<17187 17032 16966 16614 16514 16487>,
			<17110 17039 16972 16638 16528 16496>,
			<16914 17037 16953 16673 16545 16510>,
			<16778 17033 16925 16689 16552 16517>,
			<16727 16985 16873 16647 16536 16509>,
			<16691 16892 16811 16580 16510 16494>,
			<16688 16792 16772 16544 16488 16477>,
			<16690 16667 16745 16520 16465 16455>,
			<16691 16605 16707 16510 16457 16446>,
			<16693 16617 16609 16510 16459 16448>,
			<16696 16633 16516 16509 16463 16451>,
			<16698 16636 16507 16511 16467 16455>,
			<16703 16634 16514 16515 16473 16462>,
			<16708 16634 16525 16517 16480 16470>,
			<16711 16639 16549 16511 16490 16479>,
			<16714 16648 16579 16502 16498 16487>,
			<16717 16655 16599 16501 16499 16492>,
			<16721 16661 16615 16503 16499 16496>,
			<16724 16667 16629 16505 16499 16497>,
			<16726 16675 16642 16508 16483 16478>,
			<16727 16681 16651 16511 16466 16458>,
			<16727 16686 16655 16513 16465 16457>,
			<16726 16689 16656 16514 16466 16457>,
			<16725 16690 16659 16517 16468 16458>,
			<16729 16685 16662 16525 16474 16465>,
			<16736 16679 16668 16531 16476 16467>,
			<16752 16677 16689 16532 16472 16459>,
			<16769 16678 16735 16536 16464 16448>,
			<16751 16671 16737 16532 16464 16453>,
			<16767 16687 16778 16548 16474 16466>,
			<16785 16712 16828 16572 16492 16491>,
			<16811 16750 16873 16609 16521 16525>,
			<16838 16796 16922 16651 16544 16532>,
			<16851 16811 16941 16658 16510 16488>,
			<16838 16796 16915 16602 16485 16466>,
			<16820 16774 16885 16601 16491 16470>,
			<16836 16782 16894 16624 16519 16493>,
			<16836 16782 16894 16624 16519 16493>,
			<16836 16782 16894 16624 16519 16493>;
	};

	qcom,pc-temp-y5-lut {
		qcom,lut-col-legend = <(-10) 0 10 25 40 50>;
		qcom,lut-row-legend = <10000 9800 9600 9400 9200 9000>,
			<8800 8600 8400 8200 8000 7800>,
			<7600 7400 7200 7000 6800 6600>,
			<6400 6200 6000 5800 5600 5400>,
			<5200 5000 4800 4600 4400 4200>,
			<4000 3800 3600 3400 3200 3000>,
			<2800 2600 2400 2200 2000 1800>,
			<1600 1400 1200 1000 900 800>,
			<700 600 500 400 300 200>,
			<100 0>;
		qcom,lut-data = <8712 14530 12401 16230 18161 19773>,
			<8712 14120 12686 16327 18003 20761>,
			<13032 13874 13050 16432 17842 21080>,
			<17342 13749 13462 16536 17687 20950>,
			<19288 13708 13893 16630 17551 20590>,
			<19731 13716 14312 16703 17443 20219>,
			<16596 16410 14845 16778 17374 19480>,
			<11873 20507 15326 16834 17306 18576>,
			<11306 20178 15392 16781 17145 18377>,
			<13024 14640 15235 16545 16767 18742>,
			<15222 11143 15055 16248 16357 18892>,
			<18277 13278 14690 15704 15897 18566>,
			<21202 16493 14221 15118 15514 18060>,
			<20673 16836 14239 15152 15621 17461>,
			<15996 15644 15168 15751 16266 16681>,
			<13178 14902 15729 16105 16608 15995>,
			<15535 16472 15968 15327 15925 15381>,
			<19415 18814 16461 14221 15041 14939>,
			<21146 19020 17289 14292 15007 15005>,
			<21237 18001 18842 15617 15427 15569>,
			<20706 17384 19710 17212 16117 16384>,
			<17399 19570 19519 19240 18741 18164>,
			<13261 22770 19217 21049 21582 20188>,
			<12660 22148 19839 21197 21599 21209>,
			<12637 16530 21804 20766 20366 21929>,
			<12628 12854 22698 20531 19232 22146>,
			<12672 12517 19662 20632 18347 21080>,
			<12765 12339 15998 20775 17684 19451>,
			<12855 12386 15666 20769 17528 18205>,
			<12974 12702 15925 20641 17635 17022>,
			<13118 12971 16026 20719 17704 16606>,
			<13350 13073 15146 21812 17847 16711>,
			<13602 13161 14115 23088 18148 16941>,
			<13762 13360 14064 23163 19004 17833>,
			<13900 13752 14239 22725 20740 19827>,
			<13998 14031 14333 22181 21406 20619>,
			<14083 14134 14338 21457 20838 20383>,
			<14147 14199 14323 20596 20020 20099>,
			<14133 14247 14300 19763 19366 20017>,
			<14050 14304 14259 18877 18729 20010>,
			<13950 14340 14173 18327 18601 19997>,
			<13753 14360 13738 18113 19703 19646>,
			<13573 14304 13524 17837 20108 19545>,
			<13476 13949 13727 16512 18516 20280>,
			<13595 13813 13543 15779 18093 18219>,
			<13613 13726 13927 16182 17901 17942>,
			<13658 13721 13840 16101 18279 18361>,
			<13969 14066 14117 16047 18392 17465>,
			<14050 14113 14960 16299 18284 17419>,
			<14409 14497 15797 16719 17989 17081>,
			<14414 15271 16712 16990 18480 17764>,
			<14449 14456 16608 16648 19328 18604>,
			<14068 14028 15082 16434 20531 20601>,
			<13556 13929 13645 16442 23761 25088>,
			<13556 13929 13645 16442 23761 25088>,
			<13556 13929 13645 16442 23761 25088>;
	};

	qcom,pc-temp-y6-lut {
		qcom,lut-col-legend = <(-10) 0 10 25 40 50>;
		qcom,lut-row-legend = <10000 9800 9600 9400 9200 9000>,
			<8800 8600 8400 8200 8000 7800>,
			<7600 7400 7200 7000 6800 6600>,
			<6400 6200 6000 5800 5600 5400>,
			<5200 5000 4800 4600 4400 4200>,
			<4000 3800 3600 3400 3200 3000>,
			<2800 2600 2400 2200 2000 1800>,
			<1600 1400 1200 1000 900 800>,
			<700 600 500 400 300 200>,
			<100 0>;
		qcom,lut-data = <6190 5760 5455 5099 5024 5009>,
			<6244 5753 5454 5100 5024 5009>,
			<6268 5744 5453 5101 5024 5009>,
			<6268 5734 5452 5101 5024 5009>,
			<6253 5726 5451 5102 5024 5009>,
			<6229 5721 5449 5103 5024 5009>,
			<6174 5720 5447 5103 5024 5010>,
			<6111 5720 5442 5103 5025 5010>,
			<6112 5714 5436 5103 5026 5011>,
			<6170 5694 5424 5104 5027 5012>,
			<6205 5681 5418 5105 5028 5013>,
			<6192 5712 5443 5109 5029 5014>,
			<6159 5758 5477 5113 5030 5015>,
			<6096 5741 5464 5113 5032 5016>,
			<5957 5618 5387 5112 5035 5019>,
			<5879 5542 5344 5111 5038 5021>,
			<5893 5551 5356 5112 5041 5022>,
			<5913 5565 5373 5116 5045 5024>,
			<5909 5564 5374 5122 5049 5027>,
			<5871 5546 5366 5133 5053 5032>,
			<5843 5528 5354 5138 5055 5035>,
			<5834 5518 5330 5124 5048 5030>,
			<5832 5509 5301 5100 5037 5023>,
			<5843 5491 5287 5088 5029 5016>,
			<5865 5460 5279 5078 5020 5008>,
			<5888 5444 5269 5075 5017 5006>,
			<5909 5459 5252 5075 5017 5006>,
			<5930 5488 5237 5075 5018 5006>,
			<5953 5513 5241 5075 5019 5007>,
			<5977 5538 5263 5076 5021 5009>,
			<6002 5565 5288 5077 5023 5011>,
			<6026 5594 5313 5076 5026 5014>,
			<6049 5624 5340 5075 5029 5016>,
			<6070 5654 5370 5075 5030 5018>,
			<6090 5684 5401 5079 5030 5020>,
			<6109 5713 5431 5083 5030 5021>,
			<6126 5739 5458 5087 5025 5015>,
			<6142 5765 5484 5092 5020 5008>,
			<6160 5789 5508 5098 5020 5008>,
			<6178 5813 5532 5103 5021 5009>,
			<6198 5836 5557 5109 5023 5010>,
			<6219 5860 5585 5118 5027 5013>,
			<6244 5885 5617 5127 5029 5014>,
			<6277 5911 5659 5133 5027 5011>,
			<6319 5946 5707 5144 5026 5008>,
			<6307 5940 5684 5143 5028 5012>,
			<6340 5969 5709 5156 5034 5019>,
			<6383 6004 5741 5170 5042 5027>,
			<6424 6036 5766 5189 5053 5039>,
			<6473 6071 5787 5206 5059 5041>,
			<6518 6097 5804 5208 5047 5026>,
			<6566 6113 5815 5193 5041 5020>,
			<6628 6176 5861 5218 5047 5025>,
			<6758 6277 5970 5256 5062 5037>,
			<6758 6277 5970 5256 5062 5037>,
			<6758 6277 5970 5256 5062 5037>;
	};

};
